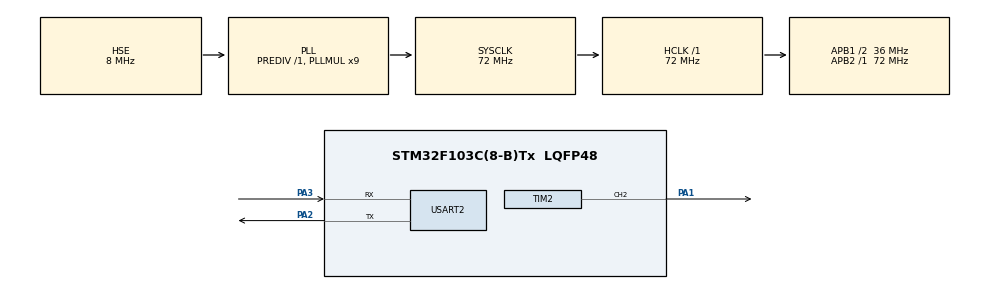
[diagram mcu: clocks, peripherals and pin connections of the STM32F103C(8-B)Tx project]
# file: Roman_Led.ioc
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Dma.Request0=TIM2_CH2/CH4
Dma.Request1=TIM4_CH1
Dma.TIM2_CH2/CH4.0.Direction=DMA_MEMORY_TO_PERIPH
Dma.TIM2_CH2/CH4.0.Instance=DMA1_Channel7
Dma.TIM2_CH2/CH4.0.MemDataAlignment=DMA_MDATAALIGN_HALFWORD
Dma.TIM2_CH2/CH4.0.MemInc=DMA_MINC_ENABLE
Dma.TIM2_CH2/CH4.0.Mode=DMA_NORMAL
Dma.TIM2_CH2/CH4.0.PeriphDataAlignment=DMA_PDATAALIGN_HALFWORD
Dma.TIM2_CH2/CH4.0.PeriphInc=DMA_PINC_DISABLE
Dma.TIM2_CH2/CH4.0.Priority=DMA_PRIORITY_LOW
Dma.TIM4_CH1.1.Direction=DMA_PERIPH_TO_MEMORY
Dma.TIM4_CH1.1.Instance=DMA1_Channel1
Dma.TIM4_CH1.1.MemDataAlignment=DMA_MDATAALIGN_HALFWORD
Dma.TIM4_CH1.1.MemInc=DMA_MINC_ENABLE
Dma.TIM4_CH1.1.Mode=DMA_NORMAL
Dma.TIM4_CH1.1.PeriphDataAlignment=DMA_PDATAALIGN_HALFWORD
Dma.TIM4_CH1.1.PeriphInc=DMA_PINC_DISABLE
Dma.TIM4_CH1.1.Priority=DMA_PRIORITY_LOW
Mcu.Family=STM32F1
Mcu.Name=STM32F103C(8-B)Tx
Mcu.Package=LQFP48
NVIC.DMA1_Channel1_IRQn=true\:0\:0\:false\:false\:true\:false\:true
NVIC.DMA1_Channel7_IRQn=true\:0\:0\:false\:false\:true\:false\:true
NVIC.PriorityGroup=NVIC_PRIORITYGROUP_4
NVIC.TIM4_IRQn=true\:0\:0\:false\:false\:true\:true\:true
NVIC.USART2_IRQn=true\:0\:0\:false\:false\:true\:true\:true
PA1.Signal=S_TIM2_CH2
PA13.Mode=Serial_Wire
PA13.Signal=SYS_JTMS-SWDIO
PA14.Mode=Serial_Wire
PA14.Signal=SYS_JTCK-SWCLK
PA2.Mode=Asynchronous
PA2.Signal=USART2_TX
PA3.Mode=Asynchronous
PA3.Signal=USART2_RX
PD0-OSC_IN.Mode=HSE-External-Oscillator
PD0-OSC_IN.Signal=RCC_OSC_IN
PD1-OSC_OUT.Mode=HSE-External-Oscillator
PD1-OSC_OUT.Signal=RCC_OSC_OUT
ProjectManager.HeapSize=0x200
ProjectManager.StackSize=0x400
ProjectManager.TargetToolchain=MDK-ARM V5
RCC.AHBFreq_Value=72000000
RCC.APB1CLKDivider=RCC_HCLK_DIV2
RCC.APB1Freq_Value=36000000
RCC.APB1TimFreq_Value=72000000
RCC.APB2Freq_Value=72000000
RCC.APB2TimFreq_Value=72000000
RCC.HCLKFreq_Value=72000000
RCC.PLLMUL=RCC_PLL_MUL9
RCC.PLLSourceVirtual=RCC_PLLSOURCE_HSE
RCC.SYSCLKFreq_VALUE=72000000
RCC.SYSCLKSource=RCC_SYSCLKSOURCE_PLLCLK
RCC.USBFreq_Value=48000000
RCC.USBPrescaler=RCC_USBCLKSOURCE_PLL_DIV1_5
SH.S_TIM2_CH2.0=TIM2_CH2,PWM Generation2 CH2
TIM2.Channel-PWM\ Generation2\ CH2=TIM_CHANNEL_2
TIM2.Period=89
TIM4.Channel-Output\ Compare1\ No\ Output=TIM_CHANNEL_1
TIM4.Prescaler=35999
USART2.VirtualMode=VM_ASYNC
VP_TIM2_VS_ClockSourceINT.Mode=Internal
VP_TIM4_VS_ClockSourceINT.Mode=Internal
VP_TIM4_VS_no_output1.Mode=Output Compare1 No Output
board=custom

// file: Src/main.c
/* USER CODE BEGIN Header */
/**
  ******************************************************************************
  * @file           : main.c
  * @brief          : Main program body
  ******************************************************************************
  ** This notice applies to any and all portions of this file
  * that are not between comment pairs USER CODE BEGIN and
  * USER CODE END. Other portions of this file, whether
  * inserted by the user or by software development tools
  * are owned by their respective copyright owners.
  *
  * COPYRIGHT(c) 2019 STMicroelectronics
  *
  * Redistribution and use in source and binary forms, with or without modification,
  * are permitted provided that the following conditions are met:
  *   1. Redistributions of source code must retain the above copyright notice,
  *      this list of conditions and the following disclaimer.
  *   2. Redistributions in binary form must reproduce the above copyright notice,
  *      this list of conditions and the following disclaimer in the documentation
  *      and/or other materials provided with the distribution.
  *   3. Neither the name of STMicroelectronics nor the names of its contributors
  *      may be used to endorse or promote products derived from this software
  *      without specific prior written permission.
  *
  * THIS SOFTWARE IS PROVIDED BY THE COPYRIGHT HOLDERS AND CONTRIBUTORS "AS IS"
  * AND ANY EXPRESS OR IMPLIED WARRANTIES, INCLUDING, BUT NOT LIMITED TO, THE
  * IMPLIED WARRANTIES OF MERCHANTABILITY AND FITNESS FOR A PARTICULAR PURPOSE ARE
  * DISCLAIMED. IN NO EVENT SHALL THE COPYRIGHT HOLDER OR CONTRIBUTORS BE LIABLE
  * FOR ANY DIRECT, INDIRECT, INCIDENTAL, SPECIAL, EXEMPLARY, OR CONSEQUENTIAL
  * DAMAGES (INCLUDING, BUT NOT LIMITED TO, PROCUREMENT OF SUBSTITUTE GOODS OR
  * SERVICES; LOSS OF USE, DATA, OR PROFITS; OR BUSINESS INTERRUPTION) HOWEVER
  * CAUSED AND ON ANY THEORY OF LIABILITY, WHETHER IN CONTRACT, STRICT LIABILITY,
  * OR TORT (INCLUDING NEGLIGENCE OR OTHERWISE) ARISING IN ANY WAY OUT OF THE USE
  * OF THIS SOFTWARE, EVEN IF ADVISED OF THE POSSIBILITY OF SUCH DAMAGE.
  *
  ******************************************************************************
  */
/* USER CODE END Header */

#include "main.h"

/* USER CODE BEGIN Includes */
#include "ws2812.h"
#include <string.h>
#include <stdlib.h>
#include <stdint.h>

/* USER CODE END Includes */

TIM_HandleTypeDef htim2;
TIM_HandleTypeDef htim4;
DMA_HandleTypeDef hdma_tim2_ch2_ch4;
DMA_HandleTypeDef hdma_tim4_ch1;

UART_HandleTypeDef huart2;

/* USER CODE BEGIN PV */
extern uint16_t BUF_DMA [ARRAY_LEN];
const int USB_BUF_SIZE = 160;
char USB_IN[USB_BUF_SIZE] = {0};
char usb_buffer[USB_BUF_SIZE] = {0};
int usb_sym_count = 0;
/* USER CODE END PV */

void SystemClock_Config(void);
static void MX_GPIO_Init(void);
static void MX_DMA_Init(void);
static void MX_TIM2_Init(void);
static void MX_USART2_UART_Init(void);
static void MX_TIM4_Init(void);

/* USER CODE BEGIN 0 */
void string_process(char* buffer)
{
	char tmpstr[300] = "log: ";
	strcat(tmpstr, buffer);
	strcat(tmpstr, "\r\n");
	HAL_UART_Transmit(&huart2, (uint8_t*)tmpstr, strlen(tmpstr), 0x1000);
	ws2812_light_from_string(buffer);
}

void UART2_RxCpltCallback()
{
	uint8_t sym;
	sym = USB_IN[0];
	if (usb_sym_count > USB_BUF_SIZE - 1)
	{
		usb_sym_count = 0;
		HAL_UART_Receive_IT(&huart2, (uint8_t*)USB_IN, 1);
		return;
	}
	usb_buffer[usb_sym_count] = sym;
	//USB_IN[usb_sym_count] = sym;
	if (sym == 0x0A)
	{
		usb_buffer[usb_sym_count + 1] = 0;
		string_process((char*)usb_buffer);
		usb_sym_count = 0;
		HAL_UART_Receive_IT(&huart2, (uint8_t*)USB_IN, 1);
		return;
	}
	usb_sym_count++;
	HAL_UART_Receive_IT(&huart2, (uint8_t*)USB_IN, 1);
}
/* USER CODE END 0 */

int main(void)
{

  /* MCU Configuration--------------------------------------------------------*/

  /* Reset of all peripherals, Initializes the Flash interface and the Systick. */
  HAL_Init();

  /* Configure the system clock */
  SystemClock_Config();

  /* Initialize all configured peripherals */
  MX_GPIO_Init();
  MX_DMA_Init();
  MX_TIM2_Init();
  MX_USART2_UART_Init();
  MX_TIM4_Init();
  /* USER CODE BEGIN 2 */
	HAL_UART_Receive_IT(&huart2,(uint8_t*)USB_IN,1);
  ws2812_init();
	//Colour c1 = {8, 1, 0};
	//Colour c2 = {0, 1, 8};
	//Colour c3 = {3, 3, 3};
	//Colour c4 = {0, 5, 3};
	//Colour cs[4] = {c1, c2, c3, c4};
	//ws2812_pattern((Colour*)cs, 4);
	//char ss[] = "2 0_3_0 0_0_8";
	//char sss[] = "6 0_4_4 4_0_4 2_2_2";
	//char sender_buffer[160];
	ws2812_all_leds(8, 3, 0);
	//HAL_Delay(5000);
  /* USER CODE END 2 */

  /* Infinite loop */
  while (1)
  {

  }
}

void SystemClock_Config(void)
{
  RCC_OscInitTypeDef RCC_OscInitStruct = {0};
  RCC_ClkInitTypeDef RCC_ClkInitStruct = {0};

  /**Initializes the CPU, AHB and APB busses clocks
  */
  RCC_OscInitStruct.OscillatorType = RCC_OSCILLATORTYPE_HSE;
  RCC_OscInitStruct.HSEState = RCC_HSE_ON;
  RCC_OscInitStruct.HSEPredivValue = RCC_HSE_PREDIV_DIV1;
  RCC_OscInitStruct.HSIState = RCC_HSI_ON;
  RCC_OscInitStruct.PLL.PLLState = RCC_PLL_ON;
  RCC_OscInitStruct.PLL.PLLSource = RCC_PLLSOURCE_HSE;
  RCC_OscInitStruct.PLL.PLLMUL = RCC_PLL_MUL9;
  if (HAL_RCC_OscConfig(&RCC_OscInitStruct) != HAL_OK)
  {
    Error_Handler();
  }
  /**Initializes the CPU, AHB and APB busses clocks
  */
  RCC_ClkInitStruct.ClockType = RCC_CLOCKTYPE_HCLK|RCC_CLOCKTYPE_SYSCLK
                              |RCC_CLOCKTYPE_PCLK1|RCC_CLOCKTYPE_PCLK2;
  RCC_ClkInitStruct.SYSCLKSource = RCC_SYSCLKSOURCE_PLLCLK;
  RCC_ClkInitStruct.AHBCLKDivider = RCC_SYSCLK_DIV1;
  RCC_ClkInitStruct.APB1CLKDivider = RCC_HCLK_DIV2;
  RCC_ClkInitStruct.APB2CLKDivider = RCC_HCLK_DIV1;

  if (HAL_RCC_ClockConfig(&RCC_ClkInitStruct, FLASH_LATENCY_2) != HAL_OK)
  {
    Error_Handler();
  }
}

static void MX_TIM2_Init(void)
{

  TIM_ClockConfigTypeDef sClockSourceConfig = {0};
  TIM_MasterConfigTypeDef sMasterConfig = {0};
  TIM_OC_InitTypeDef sConfigOC = {0};

  htim2.Instance = TIM2;
  htim2.Init.Prescaler = 0;
  htim2.Init.CounterMode = TIM_COUNTERMODE_UP;
  htim2.Init.Period = 89;
  htim2.Init.ClockDivision = TIM_CLOCKDIVISION_DIV1;
  htim2.Init.AutoReloadPreload = TIM_AUTORELOAD_PRELOAD_DISABLE;
  if (HAL_TIM_Base_Init(&htim2) != HAL_OK)
  {
    Error_Handler();
  }
  sClockSourceConfig.ClockSource = TIM_CLOCKSOURCE_INTERNAL;
  if (HAL_TIM_ConfigClockSource(&htim2, &sClockSourceConfig) != HAL_OK)
  {
    Error_Handler();
  }
  if (HAL_TIM_PWM_Init(&htim2) != HAL_OK)
  {
    Error_Handler();
  }
  sMasterConfig.MasterOutputTrigger = TIM_TRGO_RESET;
  sMasterConfig.MasterSlaveMode = TIM_MASTERSLAVEMODE_DISABLE;
  if (HAL_TIMEx_MasterConfigSynchronization(&htim2, &sMasterConfig) != HAL_OK)
  {
    Error_Handler();
  }
  sConfigOC.OCMode = TIM_OCMODE_PWM1;
  sConfigOC.Pulse = 0;
  sConfigOC.OCPolarity = TIM_OCPOLARITY_HIGH;
  sConfigOC.OCFastMode = TIM_OCFAST_DISABLE;
  if (HAL_TIM_PWM_ConfigChannel(&htim2, &sConfigOC, TIM_CHANNEL_2) != HAL_OK)
  {
    Error_Handler();
  }
  HAL_TIM_MspPostInit(&htim2);

}

static void MX_TIM4_Init(void)
{

  TIM_ClockConfigTypeDef sClockSourceConfig = {0};
  TIM_MasterConfigTypeDef sMasterConfig = {0};
  TIM_OC_InitTypeDef sConfigOC = {0};

  htim4.Instance = TIM4;
  htim4.Init.Prescaler = 35999;
  htim4.Init.CounterMode = TIM_COUNTERMODE_UP;
  htim4.Init.Period = 0;
  htim4.Init.ClockDivision = TIM_CLOCKDIVISION_DIV1;
  htim4.Init.AutoReloadPreload = TIM_AUTORELOAD_PRELOAD_DISABLE;
  if (HAL_TIM_Base_Init(&htim4) != HAL_OK)
  {
    Error_Handler();
  }
  sClockSourceConfig.ClockSource = TIM_CLOCKSOURCE_INTERNAL;
  if (HAL_TIM_ConfigClockSource(&htim4, &sClockSourceConfig) != HAL_OK)
  {
    Error_Handler();
  }
  if (HAL_TIM_OC_Init(&htim4) != HAL_OK)
  {
    Error_Handler();
  }
  sMasterConfig.MasterOutputTrigger = TIM_TRGO_RESET;
  sMasterConfig.MasterSlaveMode = TIM_MASTERSLAVEMODE_DISABLE;
  if (HAL_TIMEx_MasterConfigSynchronization(&htim4, &sMasterConfig) != HAL_OK)
  {
    Error_Handler();
  }
  sConfigOC.OCMode = TIM_OCMODE_TIMING;
  sConfigOC.Pulse = 0;
  sConfigOC.OCPolarity = TIM_OCPOLARITY_HIGH;
  sConfigOC.OCFastMode = TIM_OCFAST_DISABLE;
  if (HAL_TIM_OC_ConfigChannel(&htim4, &sConfigOC, TIM_CHANNEL_1) != HAL_OK)
  {
    Error_Handler();
  }

}

static void MX_USART2_UART_Init(void)
{

  huart2.Instance = USART2;
  huart2.Init.BaudRate = 9600;
  huart2.Init.WordLength = UART_WORDLENGTH_8B;
  huart2.Init.StopBits = UART_STOPBITS_1;
  huart2.Init.Parity = UART_PARITY_NONE;
  huart2.Init.Mode = UART_MODE_TX_RX;
  huart2.Init.HwFlowCtl = UART_HWCONTROL_NONE;
  huart2.Init.OverSampling = UART_OVERSAMPLING_16;
  if (HAL_UART_Init(&huart2) != HAL_OK)
  {
    Error_Handler();
  }

}

static void MX_DMA_Init(void)
{
  /* DMA controller clock enable */
  __HAL_RCC_DMA1_CLK_ENABLE();

  /* DMA interrupt init */
  /* DMA1_Channel1_IRQn interrupt configuration */
  HAL_NVIC_SetPriority(DMA1_Channel1_IRQn, 0, 0);
  HAL_NVIC_EnableIRQ(DMA1_Channel1_IRQn);
  /* DMA1_Channel7_IRQn interrupt configuration */
  HAL_NVIC_SetPriority(DMA1_Channel7_IRQn, 0, 0);
  HAL_NVIC_EnableIRQ(DMA1_Channel7_IRQn);

}

static void MX_GPIO_Init(void)
{

  /* GPIO Ports Clock Enable */
  __HAL_RCC_GPIOD_CLK_ENABLE();
  __HAL_RCC_GPIOA_CLK_ENABLE();

}

/* USER CODE BEGIN 4 */

void HAL_UART_RxCpltCallback(UART_HandleTypeDef *huart)
{
	if (huart == &huart2)
		UART2_RxCpltCallback();
}
/* USER CODE END 4 */

void Error_Handler(void)
{
}

/************************ (C) COPYRIGHT STMicroelectronics *****END OF FILE****/
